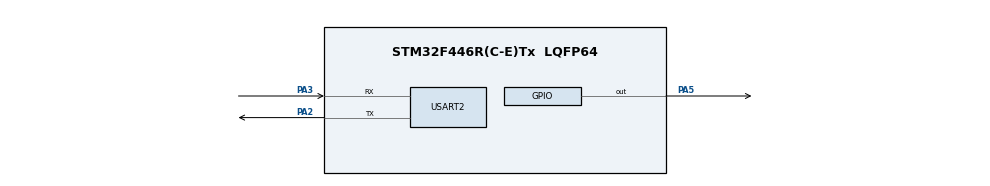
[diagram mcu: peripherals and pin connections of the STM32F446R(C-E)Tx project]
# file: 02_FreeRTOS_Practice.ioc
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FREERTOS.Tasks01=defaultTask,0,128,StartDefaultTask,Default,NULL,Dynamic,NULL,NULL;Task_LED,1,128,TaskLED,Default,NULL,Dynamic,NULL,NULL;myTask03,-3,128,StartTask03,Default,NULL,Dynamic,NULL,NULL;Task_UART,0,128,TaskUART,Default,NULL,Dynamic,NULL,NULL;Task_LED2,-2,128,TaskLEDLow,Default,NULL,Dynamic,NULL,NULL;Task_UART2,2,128,TaskUARTHigh,Default,NULL,Dynamic,NULL,NULL
Mcu.Family=STM32F4
Mcu.Name=STM32F446R(C-E)Tx
Mcu.Package=LQFP64
NVIC.PriorityGroup=NVIC_PRIORITYGROUP_4
PA2.Mode=Asynchronous
PA2.Signal=USART2_TX
PA3.Mode=Asynchronous
PA3.Signal=USART2_RX
PA5.Signal=GPIO_Output
ProjectManager.HeapSize=0x200
ProjectManager.StackSize=0x400
ProjectManager.TargetToolchain=STM32CubeIDE
RCC.CortexFreq_Value=16000000
RCC.USBFreq_Value=96000000
RCC.VCOOutputFreq_Value=192000000
USART2.VirtualMode=VM_ASYNC
VP_FREERTOS_VS_CMSIS_V1.Mode=CMSIS_V1
board=custom

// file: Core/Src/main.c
/* USER CODE BEGIN Header */
/**
  ******************************************************************************
  * @file           : main.c
  * @brief          : Main program body
  ******************************************************************************
  * @attention
  *
  * Copyright (c) 2026 STMicroelectronics.
  * All rights reserved.
  *
  * This software is licensed under terms that can be found in the LICENSE file
  * in the root directory of this software component.
  * If no LICENSE file comes with this software, it is provided AS-IS.
  *
  ******************************************************************************
  */
/* USER CODE END Header */
#include "main.h"
#include "cmsis_os.h"

/* USER CODE BEGIN Includes */
#include "stdio.h"
#include "stdint.h"
#include "semphr.h"
/* USER CODE END Includes */

/* USER CODE BEGIN PTD */
typedef struct
{
int16_t alarmActive;
int16_t errorCode;
int16_t eventCount;
} systemStatus_t;
/* USER CODE END PTD */

UART_HandleTypeDef huart2;

osThreadId defaultTaskHandle;
osThreadId Task_LEDHandle;
osThreadId myTask03Handle;
osThreadId Task_UARTHandle;
osThreadId Task_LED2Handle;
osThreadId Task_UART2Handle;
/* USER CODE BEGIN PV */
QueueHandle_t QueueHandle;
SemaphoreHandle_t AlarmSemHandle;
systemStatus_t g_systemStatus;
/* USER CODE END PV */

void SystemClock_Config(void);
static void MX_GPIO_Init(void);
static void MX_USART2_UART_Init(void);
void StartDefaultTask(void const * argument);
void TaskLED(void const * argument);
void StartTask03(void const * argument);
void TaskUART(void const * argument);
void TaskLEDLow(void const * argument);
void TaskUARTHigh(void const * argument);

int main(void)
{

  /* MCU Configuration--------------------------------------------------------*/

  /* Reset of all peripherals, Initializes the Flash interface and the Systick. */
  HAL_Init();

  /* Configure the system clock */
  SystemClock_Config();

  /* Initialize all configured peripherals */
  MX_GPIO_Init();
  MX_USART2_UART_Init();

  /* USER CODE BEGIN RTOS_SEMAPHORES */
  /* add semaphores, ... */
  AlarmSemHandle = xSemaphoreCreateBinary();
  /* USER CODE END RTOS_SEMAPHORES */

  /* USER CODE BEGIN RTOS_QUEUES */
  /* add queues, ... */
  QueueHandle = xQueueCreate(5, sizeof(systemStatus_t));
  /* USER CODE END RTOS_QUEUES */

  /* Create the thread(s) */
  /* definition and creation of defaultTask */
  osThreadDef(defaultTask, StartDefaultTask, osPriorityNormal, 0, 128);
  defaultTaskHandle = osThreadCreate(osThread(defaultTask), NULL);

  /* definition and creation of Task_LED */
  osThreadDef(Task_LED, TaskLED, osPriorityAboveNormal, 0, 128);
  Task_LEDHandle = osThreadCreate(osThread(Task_LED), NULL);

  /* definition and creation of myTask03 */
  osThreadDef(myTask03, StartTask03, osPriorityIdle, 0, 128);
  myTask03Handle = osThreadCreate(osThread(myTask03), NULL);

  /* definition and creation of Task_UART */
  osThreadDef(Task_UART, TaskUART, osPriorityNormal, 0, 128);
  Task_UARTHandle = osThreadCreate(osThread(Task_UART), NULL);

  /* definition and creation of Task_LED2 */
  osThreadDef(Task_LED2, TaskLEDLow, osPriorityLow, 0, 128);
  Task_LED2Handle = osThreadCreate(osThread(Task_LED2), NULL);

  /* definition and creation of Task_UART2 */
  osThreadDef(Task_UART2, TaskUARTHigh, osPriorityHigh, 0, 128);
  Task_UART2Handle = osThreadCreate(osThread(Task_UART2), NULL);

  /* Start scheduler */
  osKernelStart();

  /* We should never get here as control is now taken by the scheduler */

  /* Infinite loop */
  while (1)
  {

  }
}

void SystemClock_Config(void)
{
  RCC_OscInitTypeDef RCC_OscInitStruct = {0};
  RCC_ClkInitTypeDef RCC_ClkInitStruct = {0};

  /** Configure the main internal regulator output voltage
  */
  __HAL_RCC_PWR_CLK_ENABLE();
  __HAL_PWR_VOLTAGESCALING_CONFIG(PWR_REGULATOR_VOLTAGE_SCALE3);

  /** Initializes the RCC Oscillators according to the specified parameters
  * in the RCC_OscInitTypeDef structure.
  */
  RCC_OscInitStruct.OscillatorType = RCC_OSCILLATORTYPE_HSI;
  RCC_OscInitStruct.HSIState = RCC_HSI_ON;
  RCC_OscInitStruct.HSICalibrationValue = RCC_HSICALIBRATION_DEFAULT;
  RCC_OscInitStruct.PLL.PLLState = RCC_PLL_NONE;
  if (HAL_RCC_OscConfig(&RCC_OscInitStruct) != HAL_OK)
  {
    Error_Handler();
  }

  /** Initializes the CPU, AHB and APB buses clocks
  */
  RCC_ClkInitStruct.ClockType = RCC_CLOCKTYPE_HCLK|RCC_CLOCKTYPE_SYSCLK
                              |RCC_CLOCKTYPE_PCLK1|RCC_CLOCKTYPE_PCLK2;
  RCC_ClkInitStruct.SYSCLKSource = RCC_SYSCLKSOURCE_HSI;
  RCC_ClkInitStruct.AHBCLKDivider = RCC_SYSCLK_DIV1;
  RCC_ClkInitStruct.APB1CLKDivider = RCC_HCLK_DIV1;
  RCC_ClkInitStruct.APB2CLKDivider = RCC_HCLK_DIV1;

  if (HAL_RCC_ClockConfig(&RCC_ClkInitStruct, FLASH_LATENCY_0) != HAL_OK)
  {
    Error_Handler();
  }
}

static void MX_USART2_UART_Init(void)
{

  huart2.Instance = USART2;
  huart2.Init.BaudRate = 115200;
  huart2.Init.WordLength = UART_WORDLENGTH_8B;
  huart2.Init.StopBits = UART_STOPBITS_1;
  huart2.Init.Parity = UART_PARITY_NONE;
  huart2.Init.Mode = UART_MODE_TX_RX;
  huart2.Init.HwFlowCtl = UART_HWCONTROL_NONE;
  huart2.Init.OverSampling = UART_OVERSAMPLING_16;
  if (HAL_UART_Init(&huart2) != HAL_OK)
  {
    Error_Handler();
  }

}

static void MX_GPIO_Init(void)
{
  GPIO_InitTypeDef GPIO_InitStruct = {0};

  /* GPIO Ports Clock Enable */
  __HAL_RCC_GPIOA_CLK_ENABLE();

  /*Configure GPIO pin Output Level */
  HAL_GPIO_WritePin(GPIOA, GPIO_PIN_5, GPIO_PIN_RESET);

  /*Configure GPIO pin : PA5 */
  GPIO_InitStruct.Pin = GPIO_PIN_5;
  GPIO_InitStruct.Mode = GPIO_MODE_OUTPUT_PP;
  GPIO_InitStruct.Pull = GPIO_NOPULL;
  GPIO_InitStruct.Speed = GPIO_SPEED_FREQ_LOW;
  HAL_GPIO_Init(GPIOA, &GPIO_InitStruct);

}

void StartDefaultTask(void const * argument)
{
  for(;;)
  {
    osDelay(1);
  }
}

void TaskLED(void const * argument)
{
  /* USER CODE BEGIN TaskLED */
  /* Infinite loop */
  for(;;)
  {
	  HAL_GPIO_TogglePin(GPIOA, GPIO_PIN_5);
    vTaskDelay(pdMS_TO_TICKS(500));
  }
  /* USER CODE END TaskLED */
}

void StartTask03(void const * argument)
{
  for(;;)
  {
  }
}

void TaskUART(void const * argument)
{
  /* USER CODE BEGIN TaskUART */
  /* Infinite loop */
	uint32_t sayac=0;
	char buffer[50];
  for(;;)
  {
	sayac++;
  int uzunluk = sprintf(buffer, "UART Taski calisiyor putty orda mısın %lu\r\n", sayac);
  HAL_UART_Transmit(&huart2, (uint8_t*)buffer, uzunluk, 100);
  vTaskDelay(pdMS_TO_TICKS(1000));
  }
  /* USER CODE END TaskUART */
}

void TaskLEDLow(void const * argument)
{
  /* USER CODE BEGIN TaskLEDLow */
  /* Infinite loop */
	uint32_t donguSayac = 0;
  for(;;)
  {
	  donguSayac++;
	  if(donguSayac % 3 == 0)
	  {
		  g_systemStatus.alarmActive = 1;
		  g_systemStatus.errorCode = 504;
		  g_systemStatus.eventCount = donguSayac;
		  xSemaphoreGive(AlarmSemHandle);
	  }

	  HAL_GPIO_TogglePin(GPIOA, GPIO_PIN_5);
    vTaskDelay(pdMS_TO_TICKS(500));
  }
  /* USER CODE END TaskLEDLow */
}

void TaskUARTHigh(void const * argument)
{
  /* USER CODE BEGIN TaskUARTHigh */
  /* Infinite loop */
	char buffer[100];
  for(;;)
  {
	  if(xSemaphoreTake(AlarmSemHandle, portMAX_DELAY)==pdTRUE)
	  {
	  int uzunluk = sprintf(buffer, "ALARM %lu - Hata kodu:%d - Durum:%s\r\n", g_systemStatus.eventCount, g_systemStatus.errorCode, g_systemStatus.alarmActive ? "Acil" : "Normal");
	  HAL_UART_Transmit(&huart2, (uint8_t*)buffer, uzunluk, 100);
  }
  }

  /* USER CODE END TaskUARTHigh */
}

void Error_Handler(void)
{
  __disable_irq();
  while (1)
  {
  }
}
